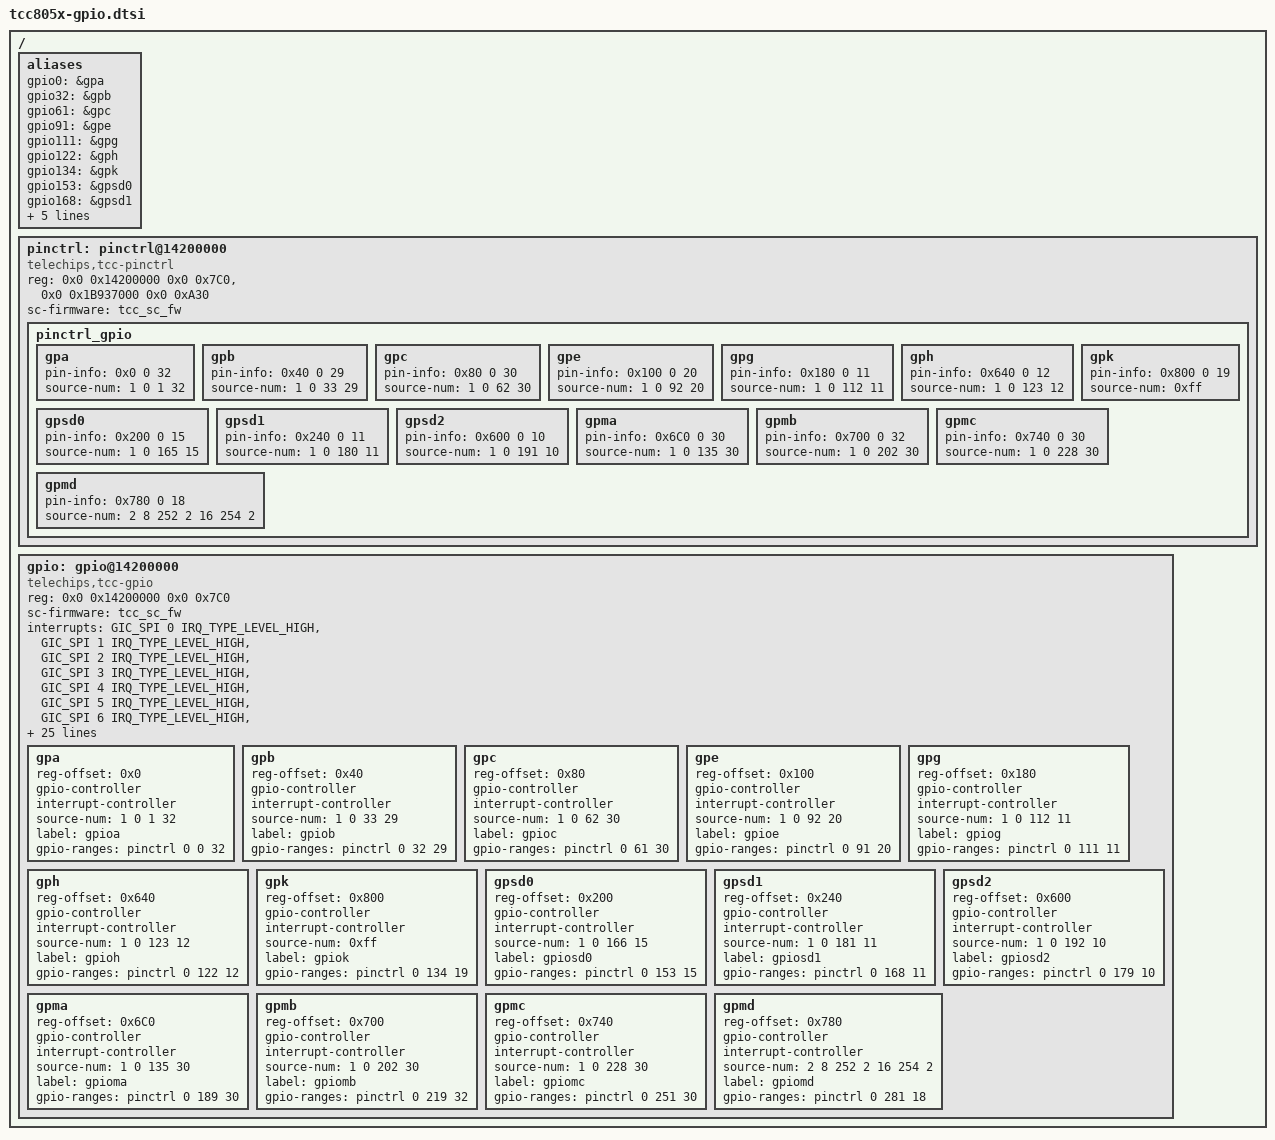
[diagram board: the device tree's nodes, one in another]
// SPDX-License-Identifier: (GPL-2.0-or-later OR MIT)
/*
 * Copyright (C) 2023 Telechips Inc.
 */

#include <dt-bindings/interrupt-controller/arm-gic.h>

/ {
	aliases: aliases {
		gpio0 = &gpa;
		gpio32 = &gpb;
		gpio61 = &gpc;
		gpio91 = &gpe;
		gpio111 = &gpg;
		gpio122 = &gph;
		gpio134 = &gpk;
		gpio153 = &gpsd0;
		gpio168 = &gpsd1;
		gpio179 = &gpsd2;
		gpio189 = &gpma;
		gpio219 = &gpmb;
		gpio251 = &gpmc;
		gpio281 = &gpmd;
	};

	pinctrl: pinctrl@14200000 {
		compatible = "telechips,tcc-pinctrl";
		reg = <0x0 0x14200000 0x0 0x7C0>,
		      <0x0 0x1B937000 0x0 0xA30>;	/* gpio, pmgpio */
		sc-firmware = <&tcc_sc_fw>;

		pinctrl_gpio {
			gpa {
				pin-info = <0x0 0 32>;
				source-num = <1 0 1 32>;
			};

			gpb {
				pin-info = <0x40 0 29>;
				source-num = <1 0 33 29>;
			};

			gpc {
				pin-info = <0x80 0 30>;
				source-num =  <1 0 62 30>;
			};

			gpe {
				pin-info = <0x100 0 20>;
				source-num = <1 0 92 20>;
			};

			gpg {
				pin-info = <0x180 0 11>;
				source-num = <1 0 112 11>;
			};

			gph {
				pin-info = <0x640 0 12>;
				source-num = <1 0 123 12>;
			};

			gpk {
				pin-info = <0x800 0 19>;
				source-num = <0xff>;
			};

			gpsd0 {
				pin-info = <0x200 0 15>;
				source-num = <1 0 165 15>;
			};

			gpsd1 {
				pin-info = <0x240 0 11>;
				source-num = <1 0 180 11>;
			};

			gpsd2 {
				pin-info = <0x600 0 10>;
				source-num = <1 0 191 10>;
			};

			gpma {
				pin-info = <0x6C0 0 30>;
				source-num = <1 0 135 30>;
			};

			gpmb {
				pin-info = <0x700 0 32>;
				source-num = <1 0 202 30>;
			};

			gpmc {
				pin-info = <0x740 0 30>;
				source-num = <1 0 228 30>;
			};

			gpmd {
				pin-info = <0x780 0 18>;
				source-num = <2 8 252 2 16 254 2>;
			};
		};
	};

	gpio: gpio@14200000 {
		compatible = "telechips,tcc-gpio";
		reg = <0x0 0x14200000 0x0 0x7C0>;
		sc-firmware = <&tcc_sc_fw>;
		interrupts = <GIC_SPI 0 IRQ_TYPE_LEVEL_HIGH>,
			     <GIC_SPI 1 IRQ_TYPE_LEVEL_HIGH>,
			     <GIC_SPI 2 IRQ_TYPE_LEVEL_HIGH>,
			     <GIC_SPI 3 IRQ_TYPE_LEVEL_HIGH>,
			     <GIC_SPI 4 IRQ_TYPE_LEVEL_HIGH>,
			     <GIC_SPI 5 IRQ_TYPE_LEVEL_HIGH>,
			     <GIC_SPI 6 IRQ_TYPE_LEVEL_HIGH>,
			     <GIC_SPI 7 IRQ_TYPE_LEVEL_HIGH>,
			     <GIC_SPI 8 IRQ_TYPE_LEVEL_HIGH>,
			     <GIC_SPI 9 IRQ_TYPE_LEVEL_HIGH>,
			     <GIC_SPI 10 IRQ_TYPE_LEVEL_HIGH>,
			     <GIC_SPI 11 IRQ_TYPE_LEVEL_HIGH>,
			     <GIC_SPI 12 IRQ_TYPE_LEVEL_HIGH>,
			     <GIC_SPI 13 IRQ_TYPE_LEVEL_HIGH>,
			     <GIC_SPI 14 IRQ_TYPE_LEVEL_HIGH>,
			     <GIC_SPI 15 IRQ_TYPE_LEVEL_HIGH>,
			     <GIC_SPI 16 IRQ_TYPE_LEVEL_HIGH>,
			     <GIC_SPI 17 IRQ_TYPE_LEVEL_HIGH>,
			     <GIC_SPI 18 IRQ_TYPE_LEVEL_HIGH>,
			     <GIC_SPI 19 IRQ_TYPE_LEVEL_HIGH>,
			     <GIC_SPI 20 IRQ_TYPE_LEVEL_HIGH>,
			     <GIC_SPI 21 IRQ_TYPE_LEVEL_HIGH>,
			     <GIC_SPI 22 IRQ_TYPE_LEVEL_HIGH>,
			     <GIC_SPI 23 IRQ_TYPE_LEVEL_HIGH>,
			     <GIC_SPI 24 IRQ_TYPE_LEVEL_HIGH>,
			     <GIC_SPI 25 IRQ_TYPE_LEVEL_HIGH>,
			     <GIC_SPI 26 IRQ_TYPE_LEVEL_HIGH>,
			     <GIC_SPI 27 IRQ_TYPE_LEVEL_HIGH>,
			     <GIC_SPI 28 IRQ_TYPE_LEVEL_HIGH>,
			     <GIC_SPI 29 IRQ_TYPE_LEVEL_HIGH>,
			     <GIC_SPI 30 IRQ_TYPE_LEVEL_HIGH>,
			     <GIC_SPI 31 IRQ_TYPE_LEVEL_HIGH>;

		gpa: gpa {
			reg-offset = <0x0>;
			gpio-controller;
			#gpio-cells = <2>;
			interrupt-controller;
			#interrupt-cells = <2>;
			source-num = <1 0 1 32>;
			label = "gpioa";
			gpio-ranges = <&pinctrl 0 0 32>;
		};

		gpb: gpb {
			reg-offset = <0x40>;
			gpio-controller;
			#gpio-cells = <2>;
			interrupt-controller;
			#interrupt-cells = <2>;
			source-num = <1 0 33 29>;
			label = "gpiob";
			gpio-ranges = <&pinctrl 0 32 29>;
		};

		gpc: gpc {
			reg-offset = <0x80>;
			gpio-controller;
			#gpio-cells = <2>;
			interrupt-controller;
			#interrupt-cells = <2>;
			source-num =  <1 0 62 30>;
			label = "gpioc";
			gpio-ranges = <&pinctrl 0 61 30>;
		};

		gpe: gpe {
			reg-offset = <0x100>;
			gpio-controller;
			#gpio-cells = <2>;
			interrupt-controller;
			#interrupt-cells = <2>;
			source-num = <1 0 92 20>;
			label = "gpioe";
			gpio-ranges = <&pinctrl 0 91 20>;
		};

		gpg: gpg {
			reg-offset = <0x180>;
			gpio-controller;
			#gpio-cells = <2>;
			interrupt-controller;
			#interrupt-cells = <2>;
			source-num = <1 0 112 11>;
			label = "gpiog";
			gpio-ranges = <&pinctrl 0 111 11>;
		};

		gph: gph {
			reg-offset = <0x640>;
			gpio-controller;
			#gpio-cells = <2>;
			interrupt-controller;
			#interrupt-cells = <2>;
			source-num = <1 0 123 12>;
			label = "gpioh";
			gpio-ranges = <&pinctrl 0 122 12>;
		};

		gpk: gpk {
			reg-offset = <0x800>;
			gpio-controller;
			#gpio-cells = <2>;
			interrupt-controller;
			#interrupt-cells = <2>;
			source-num = <0xff>;
			label = "gpiok";
			gpio-ranges = <&pinctrl 0 134 19>;
		};

		gpsd0: gpsd0 {
			reg-offset = <0x200>;
			gpio-controller;
			#gpio-cells = <2>;
			interrupt-controller;
			#interrupt-cells = <2>;
			source-num = <1 0 166 15>;
			label = "gpiosd0";
			gpio-ranges = <&pinctrl 0 153 15>;
		};

		gpsd1: gpsd1 {
			reg-offset = <0x240>;
			gpio-controller;
			#gpio-cells = <2>;
			interrupt-controller;
			#interrupt-cells = <2>;
			source-num = <1 0 181 11>;
			label = "gpiosd1";
			gpio-ranges = <&pinctrl 0 168 11>;
		};

		gpsd2: gpsd2 {
			reg-offset = <0x600>;
			gpio-controller;
			#gpio-cells = <2>;
			interrupt-controller;
			#interrupt-cells = <2>;
			source-num = <1 0 192 10>;
			label = "gpiosd2";
			gpio-ranges = <&pinctrl 0 179 10>;
		};

		gpma: gpma {
			reg-offset = <0x6C0>;
			gpio-controller;
			#gpio-cells = <2>;
			interrupt-controller;
			#interrupt-cells = <2>;
			source-num = <1 0 135 30>;
			label = "gpioma";
			gpio-ranges = <&pinctrl 0 189 30>;
		};

		gpmb: gpmb {
			reg-offset = <0x700>;
			gpio-controller;
			#gpio-cells = <2>;
			interrupt-controller;
			#interrupt-cells = <2>;
			source-num = <1 0 202 30>;
			label = "gpiomb";
			gpio-ranges = <&pinctrl 0 219 32>;
		};

		gpmc: gpmc {
			reg-offset = <0x740>;
			gpio-controller;
			#gpio-cells = <2>;
			interrupt-controller;
			#interrupt-cells = <2>;
			source-num = <1 0 228 30>;
			label = "gpiomc";
			gpio-ranges = <&pinctrl 0 251 30>;
		};

		gpmd: gpmd {
			reg-offset = <0x780>;
			gpio-controller;
			#gpio-cells = <2>;
			interrupt-controller;
			#interrupt-cells = <2>;
			source-num = <2 8 252 2 16 254 2>;
			label = "gpiomd";
			gpio-ranges = <&pinctrl 0 281 18>;
		};
	};
};
